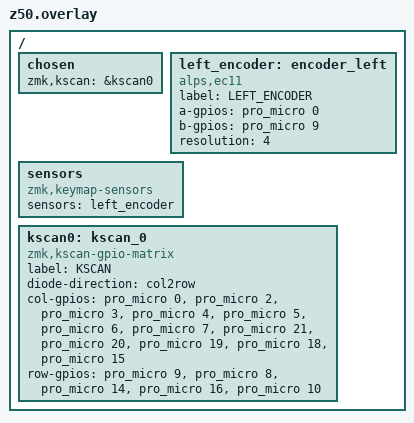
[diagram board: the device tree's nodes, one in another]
/*
 * This is free and unencumbered software released into the public domain.
 *
 * Anyone is free to copy, modify, publish, use, compile, sell, or
 * distribute this software, either in source code form or as a compiled
 * binary, for any purpose, commercial or non-commercial, and by any
 * means.
 *
 * In jurisdictions that recognize copyright laws, the author or authors
 * of this software dedicate any and all copyright interest in the
 * software to the public domain. We make this dedication for the benefit
 * of the public at large and to the detriment of our heirs and
 * successors. We intend this dedication to be an overt act of
 * relinquishment in perpetuity of all present and future rights to this
 * software under copyright law.

 * THE SOFTWARE IS PROVIDED "AS IS", WITHOUT WARRANTY OF ANY KIND,
 * EXPRESS OR IMPLIED, INCLUDING BUT NOT LIMITED TO THE WARRANTIES OF
 * MERCHANTABILITY, FITNESS FOR A PARTICULAR PURPOSE AND NONINFRINGEMENT.
 * IN NO EVENT SHALL THE AUTHORS BE LIABLE FOR ANY CLAIM, DAMAGES OR
 * OTHER LIABILITY, WHETHER IN AN ACTION OF CONTRACT, TORT OR OTHERWISE,
 * ARISING FROM, OUT OF OR IN CONNECTION WITH THE SOFTWARE OR THE USE OR
 * OTHER DEALINGS IN THE SOFTWARE.
 * 
 * For more information, please refer to <http://unlicense.org/>
 *
 * Author: zedd (2022)
 */

/{
    chosen {
        zmk,kscan = &kscan0;
    };

    left_encoder: encoder_left {
        compatible = "alps,ec11";
        label = "LEFT_ENCODER";
        a-gpios = <&pro_micro 0 (GPIO_ACTIVE_HIGH | GPIO_PULL_DOWN)>;
        b-gpios = <&pro_micro 9 (GPIO_ACTIVE_HIGH | GPIO_PULL_DOWN)>;
        resolution = <4>;
    };

    sensors {
        compatible = "zmk,keymap-sensors";
        sensors = <&left_encoder>;
    };

    kscan0: kscan_0 {
        compatible = "zmk,kscan-gpio-matrix";
        label = "KSCAN";
        diode-direction = "col2row";
        
        /* Columns */
        col-gpios
            /* Left-hand side */                        
            = <&pro_micro 0 GPIO_ACTIVE_HIGH>,
            <&pro_micro 2 GPIO_ACTIVE_HIGH>,
            <&pro_micro 3 GPIO_ACTIVE_HIGH>,
            <&pro_micro 4 GPIO_ACTIVE_HIGH>,
            <&pro_micro 5 GPIO_ACTIVE_HIGH>,
            <&pro_micro 6 GPIO_ACTIVE_HIGH>,
            <&pro_micro 7 GPIO_ACTIVE_HIGH>,
            /* Right-hand side */                        
            <&pro_micro 21 GPIO_ACTIVE_HIGH>,
            <&pro_micro 20 GPIO_ACTIVE_HIGH>,
            <&pro_micro 19 GPIO_ACTIVE_HIGH>,
            <&pro_micro 18 GPIO_ACTIVE_HIGH>,
            <&pro_micro 15 GPIO_ACTIVE_HIGH>;

        /* Rows */
        row-gpios
            = <&pro_micro 9 (GPIO_ACTIVE_HIGH | GPIO_PULL_DOWN)>,
            <&pro_micro 8 (GPIO_ACTIVE_HIGH | GPIO_PULL_DOWN)>,
            <&pro_micro 14 (GPIO_ACTIVE_HIGH | GPIO_PULL_DOWN)>,
            <&pro_micro 16 (GPIO_ACTIVE_HIGH | GPIO_PULL_DOWN)>,
            <&pro_micro 10 (GPIO_ACTIVE_HIGH | GPIO_PULL_DOWN)>;
    };

};

&left_encoder {
    status = "okay";
};
